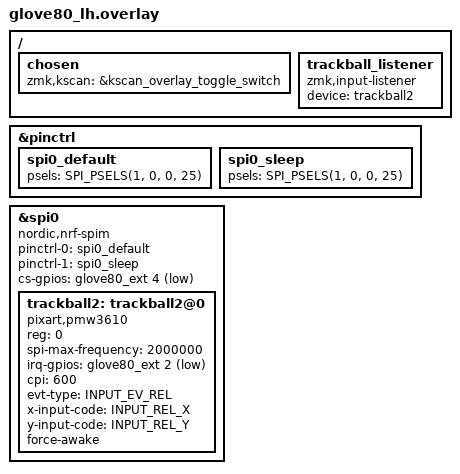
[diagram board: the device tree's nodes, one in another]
#include "glove80_shared.dtsi"

&pinctrl {
    /* SCLK = EXT6 = P1.00 */
    /* SDIO = EXT5 = P0.25 */

    spi0_default {
        psels = SPI_PSELS(1, 0, 0, 25);
    };

    spi0_sleep {
        psels = SPI_PSELS(1, 0, 0, 25);
    };
};

&spi0 {
    status = "okay";
    compatible = "nordic,nrf-spim";
    pinctrl-0 = <&spi0_default>;
    pinctrl-1 = <&spi0_sleep>;
    pinctrl-names = "default", "sleep";
    cs-gpios = <&glove80_ext 4 GPIO_ACTIVE_LOW>; /* nCS = EXT4 = P0.25 */
    /*cs-gpios = <&gpio0 25 GPIO_ACTIVE_LOW>;*/

    trackball2: trackball2@0 {
        status = "okay";
        compatible = "pixart,pmw3610";
        reg = <0>;
        spi-max-frequency = <2000000>;
        irq-gpios = <&glove80_ext 2 (GPIO_ACTIVE_LOW | GPIO_PULL_UP)>; /* Mot = EXT2 = P0.24 */
        /*irq-gpios = <&gpio0 24 (GPIO_ACTIVE_LOW | GPIO_PULL_UP)>;*/
        cpi = <600>;
        evt-type = <INPUT_EV_REL>;
        x-input-code = <INPUT_REL_X>;
        y-input-code = <INPUT_REL_Y>;

        force-awake;
        /* keep the sensor awake while ZMK activity state is ACTIVE,
           fallback to normal downshift mode after ZMK goes into IDLE / SLEEP mode.
           thus, the sensor would be a `wakeup-source` */
    };
};

/ {
    chosen {
        zmk,kscan = &kscan_overlay_toggle_switch;
    };

    // regular listener if trackball is used on split central
    trackball_listener: trackball_listener {
        compatible = "zmk,input-listener";
        status = "okay";
        device = <&trackball2>;
    };
};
